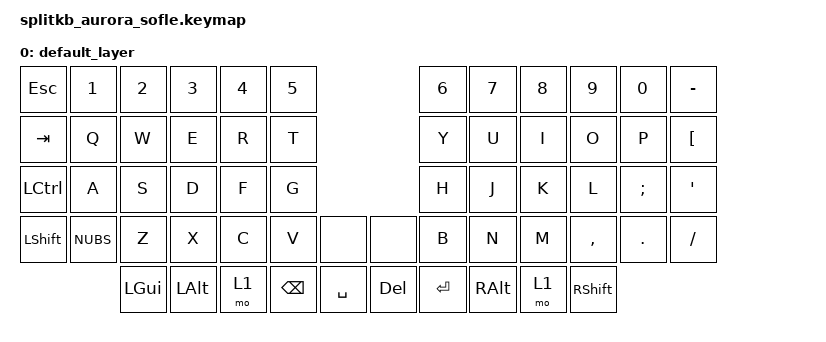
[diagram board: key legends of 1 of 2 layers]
#include <dt-bindings/zmk/modifiers.h>
#include <behaviors.dtsi>
#include <dt-bindings/zmk/keys.h>

/ {
    behaviors {
        /* [ */
        /* ] */
        /* { */
        /* } */
        /* Tap Right-Alt */
        /* AltGr + A (ä on Swiss-DE) */

        shift_f11: shift_f11 {
            compatible = "zmk,behavior-mod-morph";
            label = "SHIFT_F11";
            bindings = <&kp F11>, <&kp LS(RBKT)>;

            #binding-cells = <0>;
            mods = <(MOD_LSFT|MOD_RSFT)>;
        };

        volume_up: volume_up {
            compatible = "zmk,behavior-mod-morph";
            label = "VOLUME_UP";
            bindings = <&kp C_VOLUME_UP>, <&kp K_VOLUME_UP2>;

            #binding-cells = <0>;
            mods = <(MOD_LSFT|MOD_RSFT)>;
        };

        volume_down: volume_down {
            compatible = "zmk,behavior-mod-morph";
            label = "VOLUME_DOWN";
            bindings = <&kp C_VOLUME_DOWN>, <&kp K_VOLUME_DOWN2>;

            #binding-cells = <0>;
            mods = <(MOD_LSFT|MOD_RSFT)>;
        };
    };

    keymap {
        compatible = "zmk,keymap";

        default_layer {
            bindings = <
&kp ESC    &kp N1    &kp N2    &kp N3    &kp N4  &kp N5                          &kp N6   &kp N7    &kp N8  &kp N9     &kp N0    &kp MINUS
&kp TAB    &kp Q     &kp W     &kp E     &kp R   &kp T                           &kp Y    &kp U     &kp I   &kp O      &kp P     &kp LBKT
&kp LCTRL  &kp A     &kp S     &kp D     &kp F   &kp G                           &kp H    &kp J     &kp K   &kp L      &kp SEMI  &kp SQT
&kp LSHFT  &kp NUBS  &kp Z     &kp X     &kp C   &kp V     &none        &none    &kp B    &kp N     &kp M   &kp COMMA  &kp DOT   &kp SLASH
                     &kp LGUI  &kp LALT  &mo 1   &kp BSPC  &kp SPACE    &kp DEL  &kp RET  &kp RALT  &mo 1   &kp RSHFT
            >;
        };

        lower_layer {
            bindings = <
&kp GRAVE  &kp F1    &kp F2    &kp F3     &kp F4           &kp F5                          &kp F6      &kp F7    &kp F8          &kp F9            &kp F10       &shift_f11
&trans     &trans    &kp UP    &trans     &trans           &trans                          &trans      &trans    &kp PG_UP       &trans            &kp RA(LBKT)  &kp RA(RBKT)
&trans     &kp LEFT  &kp DOWN  &kp RIGHT  &kp NON_US_HASH  &trans                          &trans      &kp HOME  &kp PG_DN       &kp END           &kp RA(SEMI)  &kp RA(NON_US_HASH)
&trans     &trans    &trans    &trans     &trans           &volume_down  &trans    &trans  &volume_up  &trans    &kp C_PREVIOUS  &kp C_PLAY_PAUSE  &kp C_NEXT    &trans
                     &trans    &trans     &trans           &kp DEL       &trans    &trans  &trans      &trans    &trans
            >;
        };
    };
};
